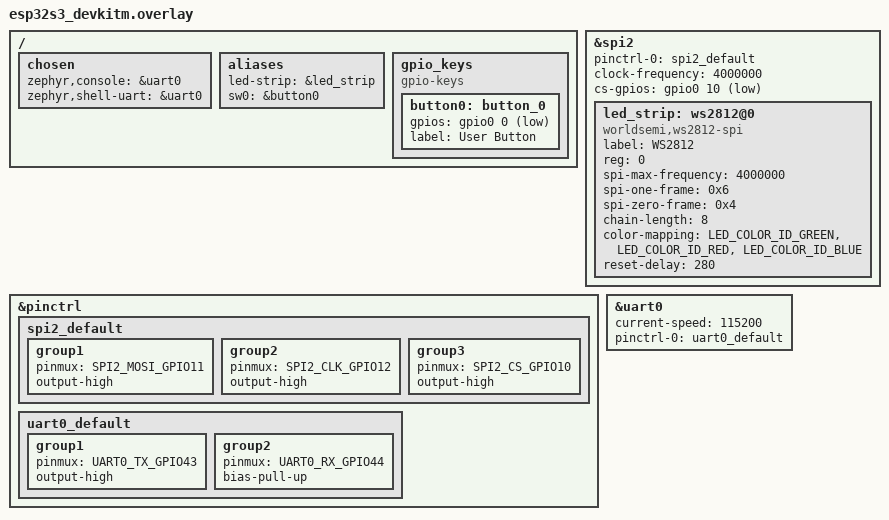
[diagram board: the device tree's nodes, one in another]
/* Fallback approach - use existing ws2812 driver binding */
/* boards/esp32s3_devkitm.overlay */

#include <zephyr/dt-bindings/led/led.h>

/ {
    chosen {
        zephyr,console = &uart0;
        zephyr,shell-uart = &uart0;
    };

    aliases {
        led-strip = &led_strip;
        sw0 = &button0;
    };

    gpio_keys {
        compatible = "gpio-keys";
        status = "okay";
        
        button0: button_0 {
            gpios = <&gpio0 0 (GPIO_PULL_UP | GPIO_ACTIVE_LOW)>;
            label = "User Button";
        };
    };
};

&spi2 {
    status = "okay";
    pinctrl-0 = <&spi2_default>;
    pinctrl-names = "default";
    clock-frequency = <4000000>;
    cs-gpios = <&gpio0 10 GPIO_ACTIVE_LOW>;
    
    led_strip: ws2812@0 {
        compatible = "worldsemi,ws2812-spi";
        label = "WS2812";
        reg = <0>; /* ignored, but necessary for SPI */
        spi-max-frequency = <4000000>;
        
        /* SPI mode for the LED strip */
        spi-one-frame = <0x6>;
        spi-zero-frame = <0x4>;
        
        /* LED strip configuration */
        chain-length = <8>;
        color-mapping = <LED_COLOR_ID_GREEN>,
                        <LED_COLOR_ID_RED>,
                        <LED_COLOR_ID_BLUE>;
        reset-delay = <280>;
    };
};

&pinctrl {
    spi2_default: spi2_default {
        group1 {
            pinmux = <SPI2_MOSI_GPIO11>;
            output-high;
        };
        group2 {
            pinmux = <SPI2_CLK_GPIO12>;
            output-high;
        };
        group3 {
            pinmux = <SPI2_CS_GPIO10>;
            output-high;
        };
    };

    uart0_default: uart0_default {
        group1 {
            pinmux = <UART0_TX_GPIO43>;
            output-high;
        };
        group2 {
            pinmux = <UART0_RX_GPIO44>;
            bias-pull-up;
        };
    };
};

&uart0 {
    status = "okay";
    current-speed = <115200>;
    pinctrl-0 = <&uart0_default>;
    pinctrl-names = "default";
};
